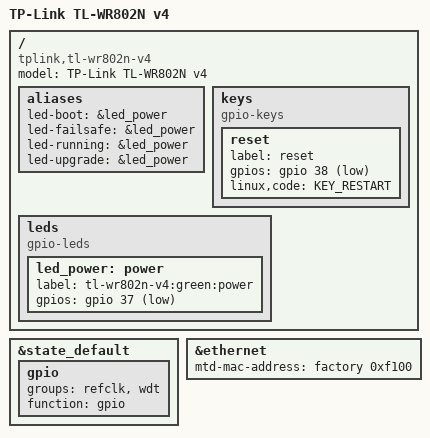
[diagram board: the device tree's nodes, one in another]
// SPDX-License-Identifier: GPL-2.0-or-later OR MIT
/dts-v1/;

#include "mt7628an_tplink_8m.dtsi"

/ {
	compatible = "tplink,tl-wr802n-v4", "mediatek,mt7628an-soc";
	model = "TP-Link TL-WR802N v4";

	aliases {
		led-boot = &led_power;
		led-failsafe = &led_power;
		led-running = &led_power;
		led-upgrade = &led_power;
	};

	keys {
		compatible = "gpio-keys";

		reset {
			label = "reset";
			gpios = <&gpio 38 GPIO_ACTIVE_LOW>;
			linux,code = <KEY_RESTART>;
		};
	};

	leds {
		compatible = "gpio-leds";

		led_power: power {
			label = "tl-wr802n-v4:green:power";
			gpios = <&gpio 37 GPIO_ACTIVE_LOW>;
		};
	};
};

&state_default {
	gpio {
		groups = "refclk", "wdt";
		function = "gpio";
	};
};

&ethernet {
	mtd-mac-address = <&factory 0xf100>;
};
